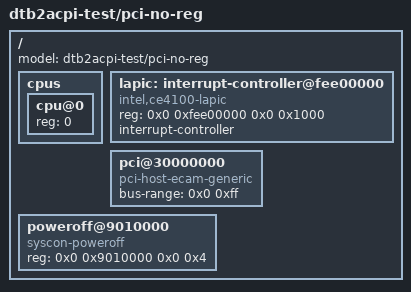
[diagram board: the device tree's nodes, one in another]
/dts-v1/;

/* pci-host-ecam-generic with bus-range but no reg — must error as
 * MissingProperty { site: PciHost, property: "reg" }.
 */
/ {
	#address-cells = <2>;
	#size-cells = <2>;
	model = "dtb2acpi-test/pci-no-reg";

	cpus {
		#address-cells = <1>;
		#size-cells = <0>;

		cpu@0 {
			device_type = "cpu";
			reg = <0>;
		};
	};

		lapic: interrupt-controller@fee00000 {
		compatible = "intel,ce4100-lapic";
		reg = <0x0 0xfee00000 0x0 0x1000>;
		interrupt-controller;
		#interrupt-cells = <2>;
	};

	pci@30000000 {
		compatible = "pci-host-ecam-generic";
		#address-cells = <3>;
		#size-cells = <2>;
		bus-range = <0x0 0xff>;
	};
		poweroff@9010000 {
		compatible = "syscon-poweroff";
		reg = <0x0 0x9010000 0x0 0x4>;
	};
};
